AUTOSAR XML (schema 4-0-3)
standard types defined: Boolean, UInt32, UInt8
package /AUTOSAR_Platform/DataConstrs
  range DC_Boolean: raw 0..1
  range DC_UInt8: raw 0..255
package /PATAC/MSM/ComponentTypes
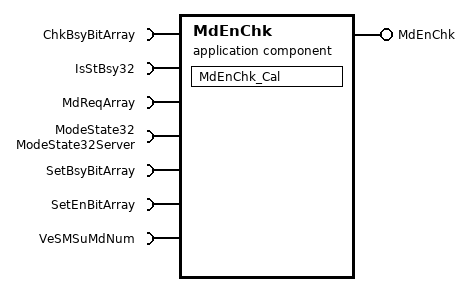
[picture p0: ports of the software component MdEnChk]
  application sw component type MdEnChk
    provide port MdEnChk: server-com-spec{operation=Cal, queue-length=1}, provided-interface=MdEnChk
    7 x require port:
      ChkBsyBitArray: nonqueued-receiver-com-spec{data-element=ChkBsyBitArray/Val, filter=data-filter-type=ALWAYS, init-value=32 x 0}, required-interface=ChkBsyBitArray
      IsStBsy32: required-com-specs=[IsStBsy32/Clear, IsStBsy32/Get, IsStBsy32/Set], required-interface=IsStBsy32
      MdReqArray: nonqueued-receiver-com-spec{data-element=MdReqArray/Val, filter=data-filter-type=ALWAYS, init-value=32 x 0}, required-interface=MdReqArray
      ModeState32: required-com-specs=[ModeState32Server/Clear, ModeState32Server/Get, ModeState32Server/Set], required-interface=ModeState32Server
      SetBsyBitArray: nonqueued-receiver-com-spec{data-element=SetBsyBitArray/Val, filter=data-filter-type=ALWAYS, init-value=32 x 0}, required-interface=SetBsyBitArray
      SetEnBitArray: nonqueued-receiver-com-spec{data-element=SetEnBitArray/Val, filter=data-filter-type=ALWAYS, init-value=32 x 0}, required-interface=SetEnBitArray
      VeSMSuMdNum: nonqueued-receiver-com-spec{data-element=VeSMSuMdNum/Val, filter=data-filter-type=ALWAYS, init-value=0}, required-interface=VeSMSuMdNum
    behavior MdEnChk_InternalBehavior
      operation invoked event OIT_MdEnChk_Cal_MdEnChk_Cal: start-on-event=MdEnChk_Cal, operation=MdEnChk.Cal
      runnable MdEnChk_Cal
        data-receive-point-by-arguments:
          5 x access:
            REC_ChkBsyBitArray_Val: accessed-variable=ChkBsyBitArray.Val
            REC_MdReqArray_Val: accessed-variable=MdReqArray.Val
            REC_SetBsyBitArray_Val: accessed-variable=SetBsyBitArray.Val
            REC_SetEnBitArray_Val: accessed-variable=SetEnBitArray.Val
            REC_VeSMSuMdNum_Val: accessed-variable=VeSMSuMdNum.Val
        sync call SC_IsStBsy32_Get: operation=IsStBsy32.Get, timeout=0
        sync call SC_IsStBsy32_Set: operation=IsStBsy32.Set, timeout=0
        sync call SC_ModeState32_Set: operation=ModeState32.Set, timeout=0
  swc implementation MdEnChk_Implementation: behavior=MdEnChk_InternalBehavior
    code-descriptors:
      code Default: artifact-descriptors=autosar-engineering-object={short-label=Default, category=SWSRC}
package /PATAC/MSM/ModeAdjust/DataType
  impl type array1x32_Boolean: category=ARRAY, sw-calibration-access=READ-ONLY, type-emitter=RTE
    element Element: array-size=32, array-size-semantics=FIXED-SIZE, implementation-data-type=Boolean
  impl type array1x32_Uint32: category=ARRAY, sw-calibration-access=READ-ONLY, type-emitter=RTE
    element Element: array-size=32, array-size-semantics=FIXED-SIZE, implementation-data-type=UInt32
package /PATAC/MSM/ModeAdjust/PortInterface
  client server interface IsStBsy32
    operation Clear
      arg ClearBit: type=UInt32, direction=IN, server-argument-impl-policy=USE-ARGUMENT-TYPE
    operation Get
      arg IsStBsy32Bit: type=UInt32, direction=OUT, server-argument-impl-policy=USE-ARGUMENT-TYPE
    operation Set
      arg SetBit: type=UInt32, direction=IN, server-argument-impl-policy=USE-ARGUMENT-TYPE
  client server interface MdEnChk
    operation Cal  # StNun: 0 :4s 1:6s 2:7s 3:4sp
  client server interface ModeState32Server
    operation Clear
      arg ClearBit: type=UInt32, direction=IN, server-argument-impl-policy=USE-ARGUMENT-TYPE
    operation Get
      arg MdEn32: type=UInt32, direction=OUT, server-argument-impl-policy=USE-ARGUMENT-TYPE
    operation Set
      arg SetBit: type=UInt32, direction=IN, server-argument-impl-policy=USE-ARGUMENT-TYPE
  5 x sender receiver interface:
    ChkBsyBitArray: invalidation-policy{data-element=ChkBsyBitArray/Val, handle-invalid=DONT-INVALIDATE}
      data Val: type=array1x32_Uint32
    MdReqArray: invalidation-policy{data-element=MdReqArray/Val, handle-invalid=DONT-INVALIDATE}
      data Val: type=array1x32_Boolean
    SetBsyBitArray: invalidation-policy{data-element=SetBsyBitArray/Val, handle-invalid=DONT-INVALIDATE}
      data Val: type=array1x32_Uint32
    SetEnBitArray: invalidation-policy{data-element=SetEnBitArray/Val, handle-invalid=DONT-INVALIDATE}
      data Val: type=array1x32_Uint32
    VeSMSuMdNum: invalidation-policy{data-element=VeSMSuMdNum/Val, handle-invalid=DONT-INVALIDATE}
      data Val: type=UInt8
